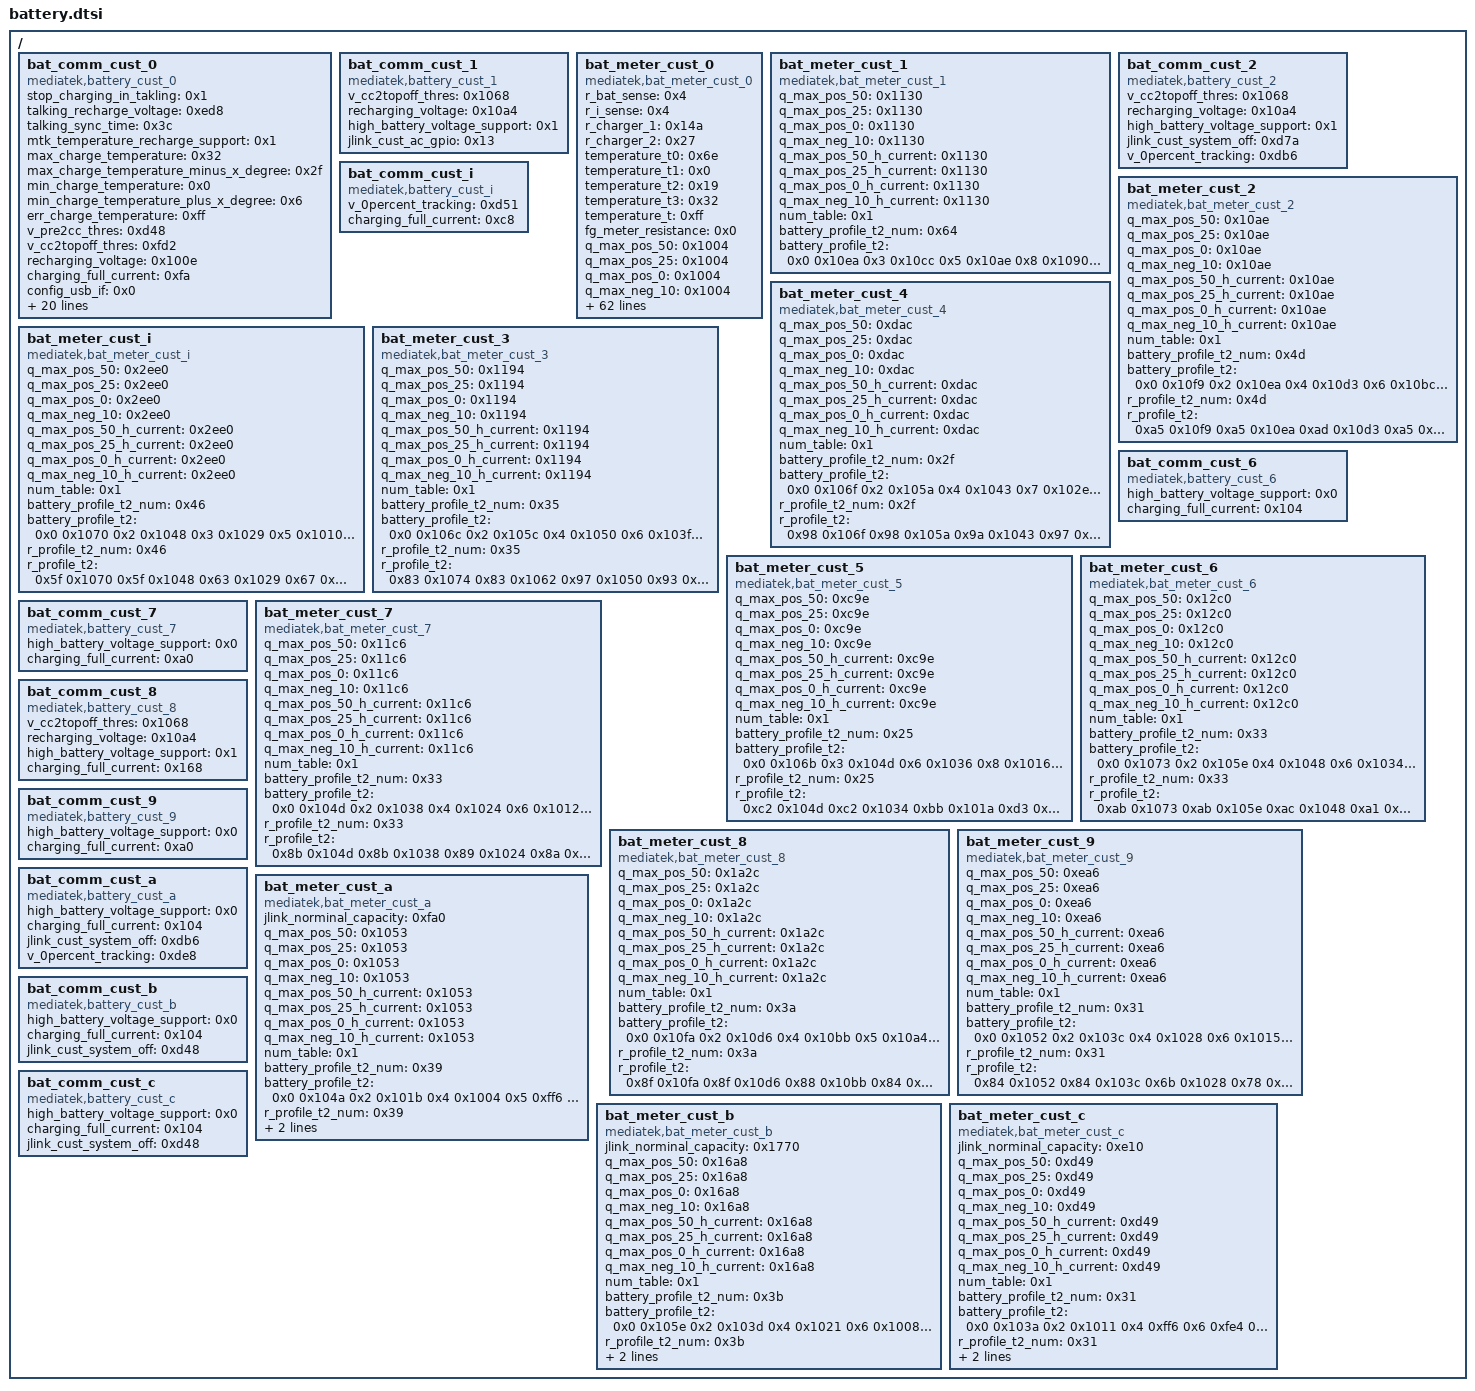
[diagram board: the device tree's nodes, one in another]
/ {
	bat_comm_cust_0 {
		compatible = "mediatek,battery_cust_0";
		stop_charging_in_takling = <0x1>;
		talking_recharge_voltage = <0xed8>;
		talking_sync_time = <0x3c>;
		mtk_temperature_recharge_support = <0x1>;
		max_charge_temperature = <0x32>;
		max_charge_temperature_minus_x_degree = <0x2f>;
		min_charge_temperature = <0x0>;
		min_charge_temperature_plus_x_degree = <0x6>;
		err_charge_temperature = <0xff>;
		v_pre2cc_thres = <0xd48>;
		v_cc2topoff_thres = <0xfd2>;
		recharging_voltage = <0x100e>;
		charging_full_current = <0xfa>;
		config_usb_if = <0x0>;
		usb_charger_current_suspend = <0x0>;
		usb_charger_current_unconfigured = <0x1b58>;
		usb_charger_current_configured = <0xc350>;
		usb_charger_current = <0xc350>;
		ac_charger_current = <0x347d8>;
		non_std_ac_charger_current = <0x347d8>;
		charging_host_charger_current = <0x347d8>;
		apple_0_5a_charger_current = <0xc350>;
		apple_1_0a_charger_current = <0x347d8>;
		apple_2_1a_charger_current = <0x347d8>;
		bat_low_temp_protect_enable = <0x0>;
		v_charger_enable = <0x0>;
		v_charger_max = <0x1964>;
		v_charger_min = <0x1130>;
		onehundred_percent_tracking_time = <0xa>;
		npercent_tracking_time = <0x14>;
		sync_to_real_tracking_time = <0x3c>;
		v_0percent_tracking = <0xd7a>;
		high_battery_voltage_support = <0x0>;
		jlink_cust_ac_gpio = <0x13>;
	};

	bat_comm_cust_1 {
		compatible = "mediatek,battery_cust_1";
		v_cc2topoff_thres = <0x1068>;
		recharging_voltage = <0x10a4>;
		high_battery_voltage_support = <0x1>;
		jlink_cust_ac_gpio = <0x13>;
	};

	bat_meter_cust_0 {
		compatible = "mediatek,bat_meter_cust_0";
		r_bat_sense = <0x4>;
		r_i_sense = <0x4>;
		r_charger_1 = <0x14a>;
		r_charger_2 = <0x27>;
		temperature_t0 = <0x6e>;
		temperature_t1 = <0x0>;
		temperature_t2 = <0x19>;
		temperature_t3 = <0x32>;
		temperature_t = <0xff>;
		fg_meter_resistance = <0x0>;
		q_max_pos_50 = <0x1004>;
		q_max_pos_25 = <0x1004>;
		q_max_pos_0 = <0x1004>;
		q_max_neg_10 = <0x1004>;
		q_max_pos_50_h_current = <0x1004>;
		q_max_pos_25_h_current = <0x1004>;
		q_max_pos_0_h_current = <0x1004>;
		q_max_neg_10_h_current = <0x1004>;
		oam_d5 = <0x1>;
		change_tracking_point = <0x1>;
		cust_tracking_point = <0x1>;
		cust_r_sense = <0x38>;
		cust_hw_cc = <0x0>;
		aging_tuning_value = <0x67>;
		cust_r_fg_offset = <0x0>;
		ocv_board_compesate = <0x0>;
		r_fg_board_base = <0x3e8>;
		r_fg_board_slope = <0x3e8>;
		car_tune_value = <0x5e>;
		car_tune_value_pb_v1 = <0x5e>;
		car_tune_value_pb_v2 = <0x5e>;
		current_detect_r_fg = <0xa>;
		minerroroffset = <0x3e8>;
		fg_vbat_average_size = <0x12>;
		r_fg_value = <0xa>;
		cust_poweron_delta_capacity_tolrance = <0x1e>;
		cust_poweron_low_capacity_tolrance = <0x5>;
		cust_poweron_max_vbat_tolrance = <0x5a>;
		cust_poweron_delta_vbat_tolrance = <0x1e>;
		cust_poweron_delta_hw_sw_ocv_capacity_tolrance = <0xa>;
		fixed_tbat_25 = <0x0>;
		vbat_normal_wakeup = <0xe10>;
		vbat_low_power_wakeup = <0xdac>;
		normal_wakeup_period = <0x1518>;
		low_power_wakeup_period = <0x12c>;
		close_poweroff_wakeup_period = <0x1e>;
		rbat_pull_up_r = <0x4204>;
		rbat_pull_up_volt = <0x708>;
		batt_temperature_table_num = <0x11>;
		batt_temperature_table = <0xffffffec 0x10a8d 0xfffffff1 0xd192 0xfffffff6 0xa60a 0xfffffffb 0x8464 0x0 0x6a53 0x5 0x5605 0xa 0x4606 0xf 0x3952 0x14 0x2f31 0x19 0x2710 0x1e 0x207b 0x23 0x1b24 0x28 0x16ca 0x2d 0x1335 0x32 0x1041 0x37 0xdcf 0x3c 0xbc6>;
		battery_profile_t0_num = <0x64>;
		battery_profile_t0 = <0x0 0x1041 0x3 0x1022 0x7 0x1010 0xa 0xffa 0xf 0xfdf 0x14 0xfb5 0x19 0xf8c 0x1e 0xf74 0x23 0xf5b 0x28 0xf43 0x2d 0xf14 0x32 0xf04 0x37 0xeee 0x3c 0xeda 0x40 0xed0 0x44 0xec8 0x46 0xec6 0x49 0xec3 0x4c 0xec2 0x4f 0xeba 0x52 0xeb5 0x53 0xeb0 0x55 0xea8 0x58 0xea5 0x5b 0xea0 0x5d 0xe82 0x5e 0xe6e 0x5f 0xe63 0x60 0xe59 0x62 0xe4a 0x63 0xdbc 0x64 0xd9d 0x64 0xd65 0x64 0xd65 0x64 0xd65 0x64 0xd65 0x64 0xd65 0x64 0xd65 0x64 0xd65 0x64 0xd65 0x64 0xd65 0x64 0xd65 0x64 0xd65 0x64 0xd65 0x64 0xd65 0x64 0xd65 0x64 0xd65 0x64 0xd65 0x64 0xd65 0x64 0xd65 0x64 0xd65 0x64 0xd65 0x64 0xd65 0x64 0xd65 0x64 0xd65 0x64 0xd65 0x64 0xd65 0x64 0xd65 0x64 0xd65 0x64 0xdaa 0x64 0xda7 0x64 0xda3 0x64 0xda0 0x64 0xd9f 0x64 0xd9b 0x64 0xd9a 0x64 0xd97 0x64 0xd97 0x64 0xd94 0x64 0xd93 0x64 0xd91 0x64 0xd90 0x64 0xd8c 0x64 0xd8b 0x64 0xd8a 0x64 0xd87 0x64 0xd87 0x64 0xd87 0x64 0xd87 0x64 0xd87 0x64 0xd87 0x64 0xd87 0x64 0xd87 0x64 0xd87 0x64 0xd87 0x64 0xd87 0x64 0xd87 0x64 0xd87 0x64 0xd87 0x64 0xd87 0x64 0xd87 0x64 0xd87 0x64 0xd87 0x64 0xc41 0x64 0xc41 0x64 0xc41 0x64 0xc41 0x64 0xc41 0x64 0xc41 0x64 0xc41>;
		battery_profile_t1_num = <0x64>;
		battery_profile_t1 = <0x0 0x1041 0x3 0x1022 0x7 0x1010 0xa 0xffa 0xf 0xfdf 0x14 0xfb5 0x19 0xf8c 0x1e 0xf74 0x23 0xf5b 0x28 0xf43 0x2d 0xf14 0x32 0xf04 0x37 0xeee 0x3c 0xeda 0x40 0xed0 0x44 0xec8 0x46 0xec6 0x49 0xec3 0x4c 0xec2 0x4f 0xeba 0x52 0xeb5 0x53 0xeb0 0x55 0xea8 0x58 0xea5 0x5b 0xea0 0x5d 0xe82 0x5e 0xe6e 0x5f 0xe63 0x60 0xe59 0x62 0xe4a 0x63 0xdbc 0x64 0xd9d 0x64 0xd65 0x64 0xd65 0x64 0xd65 0x64 0xd65 0x64 0xd65 0x64 0xd65 0x64 0xd65 0x64 0xd65 0x64 0xd65 0x64 0xd65 0x64 0xd65 0x64 0xd65 0x64 0xd65 0x64 0xd65 0x64 0xd65 0x64 0xd65 0x64 0xd65 0x64 0xd65 0x64 0xd65 0x64 0xd65 0x64 0xd65 0x64 0xd65 0x64 0xd65 0x64 0xd65 0x64 0xd65 0x64 0xd65 0x64 0xd65 0x64 0xdaa 0x64 0xda7 0x64 0xda3 0x64 0xda0 0x64 0xd9f 0x64 0xd9b 0x64 0xd9a 0x64 0xd97 0x64 0xd97 0x64 0xd94 0x64 0xd93 0x64 0xd91 0x64 0xd90 0x64 0xd8c 0x64 0xd8b 0x64 0xd8a 0x64 0xd87 0x64 0xd87 0x64 0xd87 0x64 0xd87 0x64 0xd87 0x64 0xd87 0x64 0xd87 0x64 0xd87 0x64 0xd87 0x64 0xd87 0x64 0xd87 0x64 0xd87 0x64 0xd87 0x64 0xd87 0x64 0xd87 0x64 0xd87 0x64 0xd87 0x64 0xd87 0x64 0xc41 0x64 0xc41 0x64 0xc41 0x64 0xc41 0x64 0xc41 0x64 0xc41 0x64 0xc41>;
		battery_profile_t2_num = <0x64>;
		battery_profile_t2 = <0x0 0x1041 0x3 0x1022 0x7 0x1010 0xa 0xffa 0xf 0xfdf 0x14 0xfb5 0x19 0xf8c 0x1e 0xf74 0x23 0xf5b 0x28 0xf43 0x2d 0xf14 0x32 0xf04 0x37 0xeee 0x3c 0xeda 0x40 0xed0 0x44 0xec8 0x46 0xec6 0x49 0xec3 0x4c 0xec2 0x4f 0xeba 0x52 0xeb5 0x53 0xeb0 0x55 0xea8 0x58 0xea5 0x5b 0xea0 0x5d 0xe82 0x5e 0xe6e 0x5f 0xe63 0x60 0xe59 0x62 0xe4a 0x63 0xdbc 0x64 0xd9d 0x64 0xd65 0x64 0xd65 0x64 0xd65 0x64 0xd65 0x64 0xd65 0x64 0xd65 0x64 0xd65 0x64 0xd65 0x64 0xd65 0x64 0xd65 0x64 0xd65 0x64 0xd65 0x64 0xd65 0x64 0xd65 0x64 0xd65 0x64 0xd65 0x64 0xd65 0x64 0xd65 0x64 0xd65 0x64 0xd65 0x64 0xd65 0x64 0xd65 0x64 0xd65 0x64 0xd65 0x64 0xd65 0x64 0xd65 0x64 0xd65 0x64 0xdaa 0x64 0xda7 0x64 0xda3 0x64 0xda0 0x64 0xd9f 0x64 0xd9b 0x64 0xd9a 0x64 0xd97 0x64 0xd97 0x64 0xd94 0x64 0xd93 0x64 0xd91 0x64 0xd90 0x64 0xd8c 0x64 0xd8b 0x64 0xd8a 0x64 0xd87 0x64 0xd87 0x64 0xd87 0x64 0xd87 0x64 0xd87 0x64 0xd87 0x64 0xd87 0x64 0xd87 0x64 0xd87 0x64 0xd87 0x64 0xd87 0x64 0xd87 0x64 0xd87 0x64 0xd87 0x64 0xd87 0x64 0xd87 0x64 0xd87 0x64 0xd87 0x64 0xc41 0x64 0xc41 0x64 0xc41 0x64 0xc41 0x64 0xc41 0x64 0xc41 0x64 0xc41>;
		battery_profile_t3_num = <0x64>;
		battery_profile_t3 = <0x0 0x1041 0x3 0x1022 0x7 0x1010 0xa 0xffa 0xf 0xfdf 0x14 0xfb5 0x19 0xf8c 0x1e 0xf74 0x23 0xf5b 0x28 0xf43 0x2d 0xf14 0x32 0xf04 0x37 0xeee 0x3c 0xeda 0x40 0xed0 0x44 0xec8 0x46 0xec6 0x49 0xec3 0x4c 0xec2 0x4f 0xeba 0x52 0xeb5 0x53 0xeb0 0x55 0xea8 0x58 0xea5 0x5b 0xea0 0x5d 0xe82 0x5e 0xe6e 0x5f 0xe63 0x60 0xe59 0x62 0xe4a 0x63 0xdbc 0x64 0xd9d 0x64 0xd65 0x64 0xd65 0x64 0xd65 0x64 0xd65 0x64 0xd65 0x64 0xd65 0x64 0xd65 0x64 0xd65 0x64 0xd65 0x64 0xd65 0x64 0xd65 0x64 0xd65 0x64 0xd65 0x64 0xd65 0x64 0xd65 0x64 0xd65 0x64 0xd65 0x64 0xd65 0x64 0xd65 0x64 0xd65 0x64 0xd65 0x64 0xd65 0x64 0xd65 0x64 0xd65 0x64 0xd65 0x64 0xd65 0x64 0xd65 0x64 0xdaa 0x64 0xda7 0x64 0xda3 0x64 0xda0 0x64 0xd9f 0x64 0xd9b 0x64 0xd9a 0x64 0xd97 0x64 0xd97 0x64 0xd94 0x64 0xd93 0x64 0xd91 0x64 0xd90 0x64 0xd8c 0x64 0xd8b 0x64 0xd8a 0x64 0xd87 0x64 0xd87 0x64 0xd87 0x64 0xd87 0x64 0xd87 0x64 0xd87 0x64 0xd87 0x64 0xd87 0x64 0xd87 0x64 0xd87 0x64 0xd87 0x64 0xd87 0x64 0xd87 0x64 0xd87 0x64 0xd87 0x64 0xd87 0x64 0xd87 0x64 0xd87 0x64 0xc41 0x64 0xc41 0x64 0xc41 0x64 0xc41 0x64 0xc41 0x64 0xc41 0x64 0xc41>;
		r_profile_t0_num = <0x64>;
		r_profile_t0 = <0x70 0x1041 0x70 0x103e 0x75 0x1023 0x75 0x100c 0x75 0xff5 0x73 0xfdf 0x6f 0xfcc 0x71 0xfb8 0x75 0xfa6 0x70 0xf92 0x6e 0xf84 0x75 0xf73 0x76 0xf62 0x70 0xf54 0x75 0xf42 0x71 0xf35 0x70 0xf25 0x71 0xf14 0x6e 0xf06 0x70 0xef6 0x71 0xeed 0x70 0xee2 0x70 0xed9 0x6e 0xed0 0x75 0xec5 0x75 0xec4 0x70 0xebd 0x6e 0xeb9 0x71 0xeb3 0x76 0xeb0 0x73 0xeaa 0x76 0xea6 0x75 0xea1 0x70 0xe9d 0x70 0xe95 0x70 0xe8f 0x71 0xe87 0x71 0xe7c 0x75 0xe6f 0x76 0xe60 0x75 0xe55 0x71 0xe47 0x6e 0xe2f 0x71 0xdeb 0x73 0xdbe 0xc3 0xd50 0xc3 0xd50 0xc3 0xd50 0xc3 0xd50 0xc3 0xd50 0xc3 0xd50 0xc3 0xd15 0xc3 0xd01 0xc3 0xcf7 0xc3 0xcf1 0xc3 0xced 0xc3 0xce8 0xc3 0xce6 0xc3 0xce4 0xc3 0xce0 0xc3 0xcdf 0xc3 0xce1 0xc3 0xce0 0xc3 0xce0 0xc3 0xce0 0xc3 0xcdd 0xc3 0xcd9 0xc3 0xcd9 0xc3 0xcd6 0xc3 0xcd5 0xc3 0xcd4 0xc3 0xcd4 0xc3 0xcd4 0xc3 0xcd4 0xc3 0xcd3 0xc3 0xcd2 0xc3 0xcd1 0xc3 0xcd1 0xc3 0xcd1 0xc3 0xcd1 0xc3 0xcd1 0xc3 0xcd1 0xc3 0xcd1 0xc3 0xcd1 0xc3 0xcd1 0xc3 0xcd1 0xc3 0xcd1 0xc3 0xcd1 0xc3 0xcd1 0xc3 0xcd1 0xc3 0xcd1 0xc3 0xcd1 0xc3 0xcd1 0x2bf 0xb86 0x24e 0xb85 0x1d9 0xb83 0x2b5 0xb80 0x2d5 0xb7b 0x1e3 0xb78 0x1e0 0xb73>;
		r_profile_t1_num = <0x64>;
		r_profile_t1 = <0x70 0x1041 0x70 0x103e 0x75 0x1023 0x75 0x100c 0x75 0xff5 0x73 0xfdf 0x6f 0xfcc 0x71 0xfb8 0x75 0xfa6 0x70 0xf92 0x6e 0xf84 0x75 0xf73 0x76 0xf62 0x70 0xf54 0x75 0xf42 0x71 0xf35 0x70 0xf25 0x71 0xf14 0x6e 0xf06 0x70 0xef6 0x71 0xeed 0x70 0xee2 0x70 0xed9 0x6e 0xed0 0x75 0xec5 0x75 0xec4 0x70 0xebd 0x6e 0xeb9 0x71 0xeb3 0x76 0xeb0 0x73 0xeaa 0x76 0xea6 0x75 0xea1 0x70 0xe9d 0x70 0xe95 0x70 0xe8f 0x71 0xe87 0x71 0xe7c 0x75 0xe6f 0x76 0xe60 0x75 0xe55 0x71 0xe47 0x6e 0xe2f 0x71 0xdeb 0x73 0xdbe 0xc3 0xd50 0xc3 0xd50 0xc3 0xd50 0xc3 0xd50 0xc3 0xd50 0xc3 0xd50 0xc3 0xd15 0xc3 0xd01 0xc3 0xcf7 0xc3 0xcf1 0xc3 0xced 0xc3 0xce8 0xc3 0xce6 0xc3 0xce4 0xc3 0xce0 0xc3 0xcdf 0xc3 0xce1 0xc3 0xce0 0xc3 0xce0 0xc3 0xce0 0xc3 0xcdd 0xc3 0xcd9 0xc3 0xcd9 0xc3 0xcd6 0xc3 0xcd5 0xc3 0xcd4 0xc3 0xcd4 0xc3 0xcd4 0xc3 0xcd4 0xc3 0xcd3 0xc3 0xcd2 0xc3 0xcd1 0xc3 0xcd1 0xc3 0xcd1 0xc3 0xcd1 0xc3 0xcd1 0xc3 0xcd1 0xc3 0xcd1 0xc3 0xcd1 0xc3 0xcd1 0xc3 0xcd1 0xc3 0xcd1 0xc3 0xcd1 0xc3 0xcd1 0xc3 0xcd1 0xc3 0xcd1 0xc3 0xcd1 0xc3 0xcd1 0x2bf 0xb86 0x24e 0xb85 0x1d9 0xb83 0x2b5 0xb80 0x2d5 0xb7b 0x1e3 0xb78 0x1e0 0xb73>;
		r_profile_t2_num = <0x64>;
		r_profile_t2 = <0x70 0x1041 0x70 0x103e 0x75 0x1023 0x75 0x100c 0x75 0xff5 0x73 0xfdf 0x6f 0xfcc 0x71 0xfb8 0x75 0xfa6 0x70 0xf92 0x6e 0xf84 0x75 0xf73 0x76 0xf62 0x70 0xf54 0x75 0xf42 0x71 0xf35 0x70 0xf25 0x71 0xf14 0x6e 0xf06 0x70 0xef6 0x71 0xeed 0x70 0xee2 0x70 0xed9 0x6e 0xed0 0x75 0xec5 0x75 0xec4 0x70 0xebd 0x6e 0xeb9 0x71 0xeb3 0x76 0xeb0 0x73 0xeaa 0x76 0xea6 0x75 0xea1 0x70 0xe9d 0x70 0xe95 0x70 0xe8f 0x71 0xe87 0x71 0xe7c 0x75 0xe6f 0x76 0xe60 0x75 0xe55 0x71 0xe47 0x6e 0xe2f 0x71 0xdeb 0x73 0xdbe 0xc3 0xd50 0xc3 0xd50 0xc3 0xd50 0xc3 0xd50 0xc3 0xd50 0xc3 0xd50 0xc3 0xd15 0xc3 0xd01 0xc3 0xcf7 0xc3 0xcf1 0xc3 0xced 0xc3 0xce8 0xc3 0xce6 0xc3 0xce4 0xc3 0xce0 0xc3 0xcdf 0xc3 0xce1 0xc3 0xce0 0xc3 0xce0 0xc3 0xce0 0xc3 0xcdd 0xc3 0xcd9 0xc3 0xcd9 0xc3 0xcd6 0xc3 0xcd5 0xc3 0xcd4 0xc3 0xcd4 0xc3 0xcd4 0xc3 0xcd4 0xc3 0xcd3 0xc3 0xcd2 0xc3 0xcd1 0xc3 0xcd1 0xc3 0xcd1 0xc3 0xcd1 0xc3 0xcd1 0xc3 0xcd1 0xc3 0xcd1 0xc3 0xcd1 0xc3 0xcd1 0xc3 0xcd1 0xc3 0xcd1 0xc3 0xcd1 0xc3 0xcd1 0xc3 0xcd1 0xc3 0xcd1 0xc3 0xcd1 0xc3 0xcd1 0x2bf 0xb86 0x24e 0xb85 0x1d9 0xb83 0x2b5 0xb80 0x2d5 0xb7b 0x1e3 0xb78 0x1e0 0xb73>;
		r_profile_t3_num = <0x64>;
		r_profile_t3 = <0x70 0x1041 0x70 0x103e 0x75 0x1023 0x75 0x100c 0x75 0xff5 0x73 0xfdf 0x6f 0xfcc 0x71 0xfb8 0x75 0xfa6 0x70 0xf92 0x6e 0xf84 0x75 0xf73 0x76 0xf62 0x70 0xf54 0x75 0xf42 0x71 0xf35 0x70 0xf25 0x71 0xf14 0x6e 0xf06 0x70 0xef6 0x71 0xeed 0x70 0xee2 0x70 0xed9 0x6e 0xed0 0x75 0xec5 0x75 0xec4 0x70 0xebd 0x6e 0xeb9 0x71 0xeb3 0x76 0xeb0 0x73 0xeaa 0x76 0xea6 0x75 0xea1 0x70 0xe9d 0x70 0xe95 0x70 0xe8f 0x71 0xe87 0x71 0xe7c 0x75 0xe6f 0x76 0xe60 0x75 0xe55 0x71 0xe47 0x6e 0xe2f 0x71 0xdeb 0x73 0xdbe 0xc3 0xd50 0xc3 0xd50 0xc3 0xd50 0xc3 0xd50 0xc3 0xd50 0xc3 0xd50 0xc3 0xd15 0xc3 0xd01 0xc3 0xcf7 0xc3 0xcf1 0xc3 0xced 0xc3 0xce8 0xc3 0xce6 0xc3 0xce4 0xc3 0xce0 0xc3 0xcdf 0xc3 0xce1 0xc3 0xce0 0xc3 0xce0 0xc3 0xce0 0xc3 0xcdd 0xc3 0xcd9 0xc3 0xcd9 0xc3 0xcd6 0xc3 0xcd5 0xc3 0xcd4 0xc3 0xcd4 0xc3 0xcd4 0xc3 0xcd4 0xc3 0xcd3 0xc3 0xcd2 0xc3 0xcd1 0xc3 0xcd1 0xc3 0xcd1 0xc3 0xcd1 0xc3 0xcd1 0xc3 0xcd1 0xc3 0xcd1 0xc3 0xcd1 0xc3 0xcd1 0xc3 0xcd1 0xc3 0xcd1 0xc3 0xcd1 0xc3 0xcd1 0xc3 0xcd1 0xc3 0xcd1 0xc3 0xcd1 0xc3 0xcd1 0x2bf 0xb86 0x24e 0xb85 0x1d9 0xb83 0x2b5 0xb80 0x2d5 0xb7b 0x1e3 0xb78 0x1e0 0xb73>;
	};

	bat_meter_cust_1 {
		compatible = "mediatek,bat_meter_cust_1";
		q_max_pos_50 = <0x1130>;
		q_max_pos_25 = <0x1130>;
		q_max_pos_0 = <0x1130>;
		q_max_neg_10 = <0x1130>;
		q_max_pos_50_h_current = <0x1130>;
		q_max_pos_25_h_current = <0x1130>;
		q_max_pos_0_h_current = <0x1130>;
		q_max_neg_10_h_current = <0x1130>;
		num_table = <0x1>;
		battery_profile_t2_num = <0x64>;
		battery_profile_t2 = <0x0 0x10ea 0x3 0x10cc 0x5 0x10ae 0x8 0x1090 0xb 0x1068 0xd 0x1040 0x10 0x1022 0x12 0x1003 0x15 0xfee 0x18 0xfcf 0x1a 0xfbb 0x1e 0xf8f 0x21 0xf8c 0x24 0xf75 0x27 0xf52 0x2a 0xf4a 0x2d 0xf3f 0x2f 0xf24 0x33 0xf1b 0x36 0xf08 0x39 0xef1 0x3c 0xee5 0x3e 0xee3 0x41 0xed6 0x44 0xeca 0x46 0xebf 0x49 0xeb8 0x4c 0xeb3 0x4f 0xea9 0x51 0xea7 0x52 0xea4 0x54 0xe9d 0x56 0xe93 0x57 0xe85 0x59 0xe7a 0x5a 0xe72 0x5c 0xe69 0x5d 0xe60 0x60 0xe56 0x61 0xe46 0x62 0xe36 0x63 0xdb9 0x64 0xd59 0x64 0xd59 0x64 0xd59 0x64 0xd59 0x64 0xd59 0x64 0xd59 0x64 0xd59 0x64 0xd59 0x64 0xd59 0x64 0xd59 0x64 0xd59 0x64 0xd59 0x64 0xd59 0x64 0xd59 0x64 0xd59 0x64 0xd59 0x64 0xd59 0x64 0xd59 0x64 0xd59 0x64 0xd59 0x64 0xd59 0x64 0xd59 0x64 0xd59 0x64 0xd59 0x64 0xd59 0x64 0xd59 0x64 0xd59 0x64 0xd59 0x64 0xd58 0x64 0xd55 0x64 0xd54 0x64 0xc85 0x64 0xc06 0x64 0xbd7 0x64 0xbc5 0x64 0xbc5 0x64 0xbc5 0x64 0xbc5 0x64 0xbc5 0x64 0xbc5 0x64 0xbc5 0x64 0xbc5 0x64 0xbc5 0x64 0xbc5 0x64 0xbc5 0x64 0xbc5 0x64 0xbc5 0x64 0xbc5 0x64 0xbc5 0x64 0xbc5 0x64 0xbc5 0x64 0xbc5 0x64 0xbc5 0x64 0xbc5 0x64 0xbc5 0x64 0xbc5 0x64 0xbc5 0x64 0xbc5>;
	};

	bat_comm_cust_2 {
		compatible = "mediatek,battery_cust_2";
		v_cc2topoff_thres = <0x1068>;
		recharging_voltage = <0x10a4>;
		high_battery_voltage_support = <0x1>;
		jlink_cust_system_off = <0xd7a>;
		v_0percent_tracking = <0xdb6>;
	};

	bat_meter_cust_2 {
		compatible = "mediatek,bat_meter_cust_2";
		q_max_pos_50 = <0x10ae>;
		q_max_pos_25 = <0x10ae>;
		q_max_pos_0 = <0x10ae>;
		q_max_neg_10 = <0x10ae>;
		q_max_pos_50_h_current = <0x10ae>;
		q_max_pos_25_h_current = <0x10ae>;
		q_max_pos_0_h_current = <0x10ae>;
		q_max_neg_10_h_current = <0x10ae>;
		num_table = <0x1>;
		battery_profile_t2_num = <0x4d>;
		battery_profile_t2 = <0x0 0x10f9 0x2 0x10ea 0x4 0x10d3 0x6 0x10bc 0x8 0x10a7 0xa 0x1091 0xc 0x107c 0xe 0x1067 0x10 0x1052 0x12 0x103e 0x14 0x102a 0x16 0x1016 0x17 0x1003 0x19 0xff3 0x1b 0xfe7 0x1d 0xfca 0x1f 0xfab 0x21 0xf9b 0x23 0xf92 0x25 0xf88 0x27 0xf78 0x29 0xf67 0x2b 0xf53 0x2d 0xf40 0x2f 0xf2f 0x31 0xf21 0x33 0xf15 0x35 0xf0b 0x37 0xf02 0x39 0xefa 0x3b 0xef3 0x3d 0xeec 0x3f 0xee5 0x41 0xedf 0x43 0xed9 0x45 0xed5 0x47 0xece 0x48 0xec9 0x4a 0xec1 0x4c 0xebb 0x4e 0xeb3 0x50 0xeab 0x52 0xea5 0x54 0xe9d 0x56 0xe91 0x58 0xe88 0x5a 0xe78 0x5c 0xe73 0x5e 0xe71 0x60 0xe6c 0x62 0xe48 0x63 0xe04 0x64 0xd97 0x64 0xd65 0x64 0xcf6 0x64 0xc92 0x64 0xc92 0x64 0xc92 0x64 0xc92 0x64 0xc92 0x64 0xc92 0x64 0xc92 0x64 0xc92 0x64 0xc92 0x64 0xc92 0x64 0xc92 0x64 0xc92 0x64 0xc92 0x64 0xc92 0x64 0xc92 0x64 0xc92 0x64 0xc92 0x64 0xc92 0x64 0xc92 0x64 0xc92 0x64 0xc92 0x64 0xc92>;
		r_profile_t2_num = <0x4d>;
		r_profile_t2 = <0xa5 0x10f9 0xa5 0x10ea 0xad 0x10d3 0xa5 0x10bc 0xac 0x10a7 0xa2 0x1091 0xaa 0x107c 0xa2 0x1067 0xaa 0x1052 0xae 0x103e 0xad 0x102a 0xae 0x1016 0xae 0x1003 0xb9 0xff3 0xb9 0xfe7 0xb3 0xfca 0xb0 0xfab 0xb1 0xf9b 0xba 0xf92 0xba 0xf88 0xbb 0xf78 0xb9 0xf67 0xa9 0xf53 0xa8 0xf40 0x9d 0xf2f 0xa1 0xf21 0x98 0xf15 0x99 0xf0b 0x9a 0xf02 0x9b 0xefa 0x9d 0xef3 0x8f 0xeec 0x91 0xee5 0xa6 0xedf 0x96 0xed9 0xa1 0xed5 0x9b 0xece 0x9e 0xec9 0x9f 0xec1 0x9e 0xebb 0x96 0xeb3 0x98 0xeab 0xa0 0xea5 0xa4 0xe9d 0x9f 0xe91 0x9d 0xe88 0xa1 0xe78 0xa5 0xe73 0xa9 0xe71 0xb0 0xe6c 0xad 0xe48 0xb4 0xde6 0xd1 0xd29 0xb9 0xd01 0xaa 0xc92 0xaa 0xc92 0xaa 0xc92 0xaa 0xc92 0xaa 0xc92 0xaa 0xc92 0xaa 0xc92 0xaa 0xc92 0xaa 0xc92 0xaa 0xc92 0xaa 0xc92 0xaa 0xc92 0xaa 0xc92 0xaa 0xc92 0xaa 0xc92 0xaa 0xc92 0xaa 0xc92 0xaa 0xc92 0xaa 0xc92 0xaa 0xc92 0xaa 0xc92 0xaa 0xc92 0xaa 0xc92>;
	};

	bat_comm_cust_i {
		compatible = "mediatek,battery_cust_i";
		v_0percent_tracking = <0xd51>;
		charging_full_current = <0xc8>;
	};

	bat_meter_cust_i {
		compatible = "mediatek,bat_meter_cust_i";
		q_max_pos_50 = <0x2ee0>;
		q_max_pos_25 = <0x2ee0>;
		q_max_pos_0 = <0x2ee0>;
		q_max_neg_10 = <0x2ee0>;
		q_max_pos_50_h_current = <0x2ee0>;
		q_max_pos_25_h_current = <0x2ee0>;
		q_max_pos_0_h_current = <0x2ee0>;
		q_max_neg_10_h_current = <0x2ee0>;
		num_table = <0x1>;
		battery_profile_t2_num = <0x46>;
		battery_profile_t2 = <0x0 0x1070 0x2 0x1048 0x3 0x1029 0x5 0x1010 0x7 0xff9 0x8 0xfe5 0xa 0xfd1 0xb 0xfbe 0xd 0xfac 0xf 0xf9a 0x10 0xf88 0x12 0xf77 0x14 0xf67 0x15 0xf57 0x17 0xf46 0x18 0xf37 0x1a 0xf27 0x1c 0xf18 0x1d 0xf09 0x1f 0xefb 0x21 0xeed 0x22 0xedf 0x24 0xed2 0x25 0xec5 0x27 0xeb9 0x29 0xeae 0x2a 0xea3 0x2c 0xe99 0x2e 0xe8e 0x2f 0xe82 0x31 0xe74 0x32 0xe66 0x34 0xe5a 0x36 0xe50 0x37 0xe48 0x39 0xe42 0x3b 0xe3c 0x3c 0xe37 0x3e 0xe32 0x40 0xe2f 0x41 0xe2a 0x43 0xe26 0x44 0xe22 0x46 0xe1f 0x48 0xe1c 0x49 0xe17 0x4b 0xe13 0x4d 0xe10 0x4e 0xe0b 0x50 0xe06 0x51 0xdff 0x53 0xdf7 0x55 0xdee 0x56 0xde4 0x58 0xddb 0x5a 0xdcf 0x5b 0xdc9 0x5d 0xdbf 0x5e 0xdb3 0x60 0xda7 0x62 0xd99 0x63 0xd8c 0x64 0xd7d 0x64 0xd73 0x64 0xd69 0x64 0xd5b 0x64 0xd42 0x64 0xd03 0x64 0xce7 0x64 0xce1>;
		r_profile_t2_num = <0x46>;
		r_profile_t2 = <0x5f 0x1070 0x5f 0x1048 0x63 0x1029 0x67 0x1010 0x52 0xff9 0x5b 0xfe5 0x5f 0xfd1 0x5d 0xfbe 0x56 0xfac 0x54 0xf9a 0x5f 0xf88 0x54 0xf77 0x60 0xf67 0x62 0xf57 0x5b 0xf46 0x54 0xf37 0x5f 0xf27 0x52 0xf18 0x54 0xf09 0x53 0xefb 0x5e 0xeed 0x5f 0xedf 0x68 0xed2 0x56 0xec5 0x5d 0xeb9 0x68 0xeae 0x64 0xea3 0x6b 0xe99 0x5e 0xe8e 0x63 0xe82 0x65 0xe74 0x65 0xe66 0x64 0xe5a 0x5c 0xe50 0x5b 0xe48 0x53 0xe42 0x5b 0xe3c 0x5b 0xe37 0x59 0xe32 0x58 0xe2f 0x53 0xe2a 0x58 0xe26 0x5b 0xe22 0x59 0xe1f 0x56 0xe1c 0x5b 0xe17 0x5e 0xe13 0x59 0xe10 0x58 0xe0b 0x5f 0xe06 0x59 0xdff 0x5e 0xdf7 0x55 0xdee 0x58 0xde4 0x64 0xddb 0x52 0xdcf 0x65 0xdc9 0x62 0xdbf 0x67 0xdb3 0x5f 0xda7 0x56 0xd99 0x5c 0xd8c 0x66 0xd7d 0x6a 0xd73 0x64 0xd69 0x7f 0xd5b 0x94 0xd42 0xb5 0xd03 0xb6 0xce7 0xb6 0xce1>;
	};

	bat_meter_cust_3 {
		compatible = "mediatek,bat_meter_cust_3";
		q_max_pos_50 = <0x1194>;
		q_max_pos_25 = <0x1194>;
		q_max_pos_0 = <0x1194>;
		q_max_neg_10 = <0x1194>;
		q_max_pos_50_h_current = <0x1194>;
		q_max_pos_25_h_current = <0x1194>;
		q_max_pos_0_h_current = <0x1194>;
		q_max_neg_10_h_current = <0x1194>;
		num_table = <0x1>;
		battery_profile_t2_num = <0x35>;
		battery_profile_t2 = <0x0 0x106c 0x2 0x105c 0x4 0x1050 0x6 0x103f 0x8 0x102d 0xa 0x101b 0xc 0x100a 0xe 0xff9 0x10 0xfea 0x12 0xfd9 0x13 0xfc7 0x15 0xfb8 0x17 0xfa9 0x19 0xf9a 0x1b 0xf8a 0x1d 0xf7e 0x1f 0xf70 0x21 0xf60 0x23 0xf4d 0x25 0xf3b 0x27 0xf2b 0x29 0xf1f 0x2b 0xf14 0x2d 0xf0b 0x2f 0xf03 0x31 0xefb 0x33 0xef3 0x35 0xeed 0x37 0xee7 0x39 0xee0 0x3a 0xeda 0x3c 0xed5 0x3e 0xecf 0x40 0xeca 0x42 0xec6 0x44 0xec1 0x46 0xebc 0x48 0xeb7 0x4a 0xeb1 0x4c 0xea9 0x4e 0xea0 0x50 0xe99 0x52 0xe8c 0x54 0xe7d 0x56 0xe6d 0x58 0xe68 0x5a 0xe66 0x5c 0xe64 0x5e 0xe61 0x5f 0xe57 0x61 0xe1f 0x63 0xdbf 0x64 0xd89>;
		r_profile_t2_num = <0x35>;
		r_profile_t2 = <0x83 0x1074 0x83 0x1062 0x97 0x1050 0x93 0x103f 0x96 0x102d 0x86 0x101b 0x88 0x100a 0x9a 0xff9 0x87 0xfea 0x95 0xfd9 0x8b 0xfc7 0x9a 0xfb8 0x90 0xfa9 0xa5 0xf9a 0x99 0xf8a 0xae 0xf7e 0x9d 0xf70 0x94 0xf60 0x9b 0xf4d 0x99 0xf3b 0x81 0xf2b 0x86 0xf1f 0x90 0xf14 0x7a 0xf0b 0x82 0xf03 0x80 0xefb 0x80 0xef3 0x86 0xeed 0x8d 0xee7 0x98 0xee0 0x96 0xeda 0x93 0xed5 0x87 0xecf 0x9c 0xeca 0x98 0xec6 0x97 0xec1 0x83 0xebc 0x7b 0xeb7 0x96 0xeb1 0x8c 0xea9 0x8d 0xea0 0x90 0xe99 0x93 0xe8c 0x93 0xe7d 0x87 0xe6d 0x89 0xe68 0x89 0xe66 0x9a 0xe64 0xa1 0xe61 0xa9 0xe57 0x9f 0xe1f 0xa8 0xdbf 0xa7 0xd25>;
	};

	bat_meter_cust_4 {
		compatible = "mediatek,bat_meter_cust_4";
		q_max_pos_50 = <0xdac>;
		q_max_pos_25 = <0xdac>;
		q_max_pos_0 = <0xdac>;
		q_max_neg_10 = <0xdac>;
		q_max_pos_50_h_current = <0xdac>;
		q_max_pos_25_h_current = <0xdac>;
		q_max_pos_0_h_current = <0xdac>;
		q_max_neg_10_h_current = <0xdac>;
		num_table = <0x1>;
		battery_profile_t2_num = <0x2f>;
		battery_profile_t2 = <0x0 0x106f 0x2 0x105a 0x4 0x1043 0x7 0x102e 0x9 0x101b 0xb 0x1009 0xd 0xff8 0xf 0xfea 0x12 0xfdd 0x14 0xfd0 0x16 0xfc5 0x18 0xfba 0x1a 0xfae 0x1d 0xfa0 0x1f 0xf91 0x21 0xf81 0x23 0xf6e 0x25 0xf5b 0x28 0xf4a 0x2a 0xf3c 0x2c 0xf30 0x2e 0xf26 0x30 0xf1d 0x33 0xf13 0x35 0xf0b 0x37 0xf03 0x39 0xefb 0x3b 0xef2 0x3e 0xeea 0x40 0xee3 0x42 0xedb 0x44 0xed2 0x46 0xec6 0x49 0xeba 0x4b 0xeae 0x4d 0xea4 0x4f 0xe9c 0x51 0xe94 0x54 0xe89 0x56 0xe7f 0x58 0xe73 0x5a 0xe67 0x5c 0xe63 0x5f 0xe5b 0x61 0xe33 0x63 0xdd9 0x64 0xd98>;
		r_profile_t2_num = <0x2f>;
		r_profile_t2 = <0x98 0x106f 0x98 0x105a 0x9a 0x1043 0x97 0x102e 0x9e 0x101b 0x90 0x1009 0x9b 0xff8 0xab 0xfea 0x9f 0xfdd 0xa4 0xfd0 0xaa 0xfc5 0xab 0xfba 0xa9 0xfae 0xb8 0xfa0 0xa2 0xf91 0xb4 0xf81 0xa3 0xf6e 0x9b 0xf5b 0xa3 0xf4a 0x96 0xf3c 0x9d 0xf30 0xa0 0xf26 0x97 0xf1d 0x9a 0xf13 0x96 0xf0b 0x9d 0xf03 0x96 0xefb 0x96 0xef2 0x9b 0xeea 0xa5 0xee3 0x99 0xedb 0xa5 0xed2 0x92 0xec6 0xa2 0xeba 0x9d 0xeae 0x9d 0xea4 0x9e 0xe9c 0x99 0xe94 0xa0 0xe89 0x95 0xe7f 0x86 0xe73 0x93 0xe67 0x96 0xe63 0x9d 0xe5b 0xa9 0xe33 0xa9 0xdd9 0xae 0xd40>;
	};

	bat_meter_cust_5 {
		compatible = "mediatek,bat_meter_cust_5";
		q_max_pos_50 = <0xc9e>;
		q_max_pos_25 = <0xc9e>;
		q_max_pos_0 = <0xc9e>;
		q_max_neg_10 = <0xc9e>;
		q_max_pos_50_h_current = <0xc9e>;
		q_max_pos_25_h_current = <0xc9e>;
		q_max_pos_0_h_current = <0xc9e>;
		q_max_neg_10_h_current = <0xc9e>;
		num_table = <0x1>;
		battery_profile_t2_num = <0x25>;
		battery_profile_t2 = <0x0 0x106b 0x3 0x104d 0x6 0x1036 0x8 0x1016 0xb 0xfff 0xe 0xfdd 0x11 0xfba 0x14 0xfa6 0x17 0xf94 0x19 0xf83 0x1c 0xf71 0x1f 0xf60 0x22 0xf42 0x25 0xf24 0x27 0xf15 0x2a 0xf08 0x2d 0xefc 0x30 0xef2 0x33 0xee9 0x35 0xee0 0x38 0xed9 0x3b 0xed2 0x3e 0xecd 0x41 0xec6 0x44 0xec0 0x46 0xeb8 0x49 0xeb1 0x4c 0xea8 0x4f 0xe9f 0x52 0xe93 0x54 0xe83 0x57 0xe72 0x5a 0xe66 0x5d 0xe44 0x60 0xe28 0x62 0xdec 0x64 0xd9c>;
		r_profile_t2_num = <0x25>;
		r_profile_t2 = <0xc2 0x104d 0xc2 0x1034 0xbb 0x101a 0xd3 0x1002 0xac 0xfeb 0xbf 0xfd3 0xb0 0xfba 0xe3 0xfa6 0xdf 0xf94 0xd5 0xf83 0x102 0xf71 0xe6 0xf60 0xf2 0xf42 0xc4 0xf24 0xa9 0xf15 0xca 0xf08 0xbe 0xefc 0xc1 0xef2 0xcf 0xee9 0xcd 0xee0 0xba 0xed9 0xc8 0xed2 0xdc 0xecd 0xd5 0xec6 0xca 0xec0 0xbe 0xeb8 0xc5 0xeb1 0xb7 0xea8 0xd9 0xe9f 0xd6 0xe93 0xca 0xe83 0xcf 0xe72 0xdc 0xe66 0xd9 0xe62 0x107 0xe55 0x120 0xe00 0x17e 0xd3d>;
	};

	bat_comm_cust_6 {
		compatible = "mediatek,battery_cust_6";
		high_battery_voltage_support = <0x0>;
		charging_full_current = <0x104>;
	};

	bat_meter_cust_6 {
		compatible = "mediatek,bat_meter_cust_6";
		q_max_pos_50 = <0x12c0>;
		q_max_pos_25 = <0x12c0>;
		q_max_pos_0 = <0x12c0>;
		q_max_neg_10 = <0x12c0>;
		q_max_pos_50_h_current = <0x12c0>;
		q_max_pos_25_h_current = <0x12c0>;
		q_max_pos_0_h_current = <0x12c0>;
		q_max_neg_10_h_current = <0x12c0>;
		num_table = <0x1>;
		battery_profile_t2_num = <0x33>;
		battery_profile_t2 = <0x0 0x1073 0x2 0x105e 0x4 0x1048 0x6 0x1034 0x8 0x1021 0xa 0x100d 0xc 0xffc 0xe 0xfeb 0x10 0xfdd 0x12 0xfc7 0x14 0xfb3 0x16 0xfa1 0x18 0xf94 0x1a 0xf8b 0x1c 0xf7e 0x1e 0xf71 0x20 0xf63 0x22 0xf57 0x25 0xf4a 0x27 0xf3a 0x29 0xf2b 0x2b 0xf1c 0x2d 0xf0f 0x2f 0xf04 0x31 0xefb 0x33 0xef2 0x35 0xeeb 0x37 0xee4 0x39 0xedf 0x3b 0xed9 0x3d 0xed4 0x3f 0xed0 0x41 0xecb 0x43 0xec7 0x45 0xec2 0x47 0xebd 0x49 0xeb7 0x4b 0xeb0 0x4d 0xea9 0x4f 0xea2 0x51 0xe9c 0x53 0xe94 0x55 0xe8a 0x57 0xe7f 0x59 0xe71 0x5b 0xe69 0x5d 0xe66 0x5f 0xe60 0x61 0xe2f 0x63 0xdc5 0x64 0xd6d>;
		r_profile_t2_num = <0x33>;
		r_profile_t2 = <0xab 0x1073 0xab 0x105e 0xac 0x1048 0xa1 0x1034 0xb2 0x1021 0xac 0x100d 0xbd 0xffc 0xae 0xfeb 0xac 0xfdd 0x9d 0xfc7 0xa4 0xfb3 0xab 0xfa1 0x9e 0xf94 0xc1 0xf8b 0xc1 0xf7e 0xbf 0xf71 0xaf 0xf63 0xcb 0xf57 0xb0 0xf4a 0xb9 0xf3a 0xb7 0xf2b 0xb5 0xf1c 0xab 0xf0f 0xb3 0xf04 0xaf 0xefb 0xb8 0xef2 0xaa 0xeeb 0x9c 0xee4 0xb8 0xedf 0xa6 0xed9 0xa9 0xed4 0xb9 0xed0 0xbb 0xecb 0xbc 0xec7 0xa8 0xec2 0xc1 0xebd 0xa7 0xeb7 0xa1 0xeb0 0xb0 0xea9 0xa2 0xea2 0xae 0xe9c 0xa4 0xe94 0xae 0xe8a 0xac 0xe7f 0xaf 0xe71 0xa7 0xe69 0xa8 0xe66 0xb2 0xe60 0xba 0xe2f 0xd0 0xdc5 0xef 0xcf2>;
	};

	bat_comm_cust_7 {
		compatible = "mediatek,battery_cust_7";
		high_battery_voltage_support = <0x0>;
		charging_full_current = <0xa0>;
	};

	bat_meter_cust_7 {
		compatible = "mediatek,bat_meter_cust_7";
		q_max_pos_50 = <0x11c6>;
		q_max_pos_25 = <0x11c6>;
		q_max_pos_0 = <0x11c6>;
		q_max_neg_10 = <0x11c6>;
		q_max_pos_50_h_current = <0x11c6>;
		q_max_pos_25_h_current = <0x11c6>;
		q_max_pos_0_h_current = <0x11c6>;
		q_max_neg_10_h_current = <0x11c6>;
		num_table = <0x1>;
		battery_profile_t2_num = <0x33>;
		battery_profile_t2 = <0x0 0x104d 0x2 0x1038 0x4 0x1024 0x6 0x1012 0x8 0x1000 0xa 0xfef 0xc 0xfe6 0xe 0xfd4 0x10 0xfb8 0x12 0xfa2 0x14 0xf95 0x16 0xf8e 0x18 0xf82 0x1a 0xf76 0x1c 0xf69 0x1e 0xf5a 0x20 0xf48 0x22 0xf36 0x24 0xf25 0x26 0xf18 0x28 0xf0c 0x2a 0xf04 0x2c 0xefb 0x2e 0xef4 0x30 0xeed 0x32 0xee5 0x34 0xedf 0x36 0xeda 0x38 0xed4 0x3a 0xece 0x3c 0xeca 0x3e 0xec4 0x40 0xebf 0x42 0xeba 0x44 0xeb5 0x46 0xeb0 0x48 0xeab 0x4b 0xea6 0x4d 0xea1 0x4f 0xe9b 0x51 0xe95 0x53 0xe8c 0x55 0xe83 0x57 0xe79 0x59 0xe6e 0x5b 0xe6a 0x5d 0xe67 0x5f 0xe63 0x61 0xe43 0x63 0xdf3 0x64 0xd6d>;
		r_profile_t2_num = <0x33>;
		r_profile_t2 = <0x8b 0x104d 0x8b 0x1038 0x89 0x1024 0x8a 0x1012 0x95 0x1000 0x8a 0xfef 0x91 0xfe6 0x9c 0xfd4 0x90 0xfb8 0x98 0xfa2 0x93 0xf95 0x94 0xf8e 0x93 0xf82 0x95 0xf76 0x94 0xf69 0xa6 0xf5a 0x98 0xf48 0x94 0xf36 0x86 0xf25 0x97 0xf18 0x88 0xf0c 0x95 0xf04 0x8e 0xefb 0x8a 0xef4 0x8a 0xeed 0x93 0xee5 0x96 0xedf 0x93 0xeda 0x96 0xed4 0x94 0xece 0x99 0xeca 0xa2 0xec4 0x96 0xebf 0x8e 0xeba 0x90 0xeb5 0x96 0xeb0 0x91 0xeab 0x97 0xea6 0x94 0xea1 0x88 0xe9b 0x96 0xe95 0x98 0xe8c 0x9e 0xe83 0xa4 0xe79 0x9e 0xe6e 0x95 0xe6a 0xa4 0xe67 0xaa 0xe63 0xa9 0xe43 0x97 0xdf3 0xa1 0xd6d>;
	};

	bat_comm_cust_8 {
		compatible = "mediatek,battery_cust_8";
		v_cc2topoff_thres = <0x1068>;
		recharging_voltage = <0x10a4>;
		high_battery_voltage_support = <0x1>;
		charging_full_current = <0x168>;
	};

	bat_meter_cust_8 {
		compatible = "mediatek,bat_meter_cust_8";
		q_max_pos_50 = <0x1a2c>;
		q_max_pos_25 = <0x1a2c>;
		q_max_pos_0 = <0x1a2c>;
		q_max_neg_10 = <0x1a2c>;
		q_max_pos_50_h_current = <0x1a2c>;
		q_max_pos_25_h_current = <0x1a2c>;
		q_max_pos_0_h_current = <0x1a2c>;
		q_max_neg_10_h_current = <0x1a2c>;
		num_table = <0x1>;
		battery_profile_t2_num = <0x3a>;
		battery_profile_t2 = <0x0 0x10fa 0x2 0x10d6 0x4 0x10bb 0x5 0x10a4 0x7 0x108e 0x9 0x107b 0xb 0x1066 0xc 0x1055 0xe 0x1042 0x10 0x102f 0x12 0x101d 0x13 0x100c 0x15 0xffa 0x17 0xfee 0x19 0xfe4 0x1b 0xfca 0x1c 0xfae 0x1e 0xf9c 0x20 0xf8e 0x22 0xf88 0x23 0xf80 0x25 0xf73 0x27 0xf65 0x29 0xf55 0x2b 0xf44 0x2c 0xf34 0x2e 0xf25 0x30 0xf19 0x32 0xf0f 0x33 0xf06 0x35 0xefd 0x37 0xef6 0x39 0xeef 0x3a 0xee8 0x3c 0xee2 0x3e 0xedd 0x40 0xed7 0x42 0xed2 0x43 0xece 0x45 0xec9 0x47 0xec4 0x49 0xebf 0x4a 0xeb9 0x4c 0xeb2 0x4e 0xeab 0x50 0xea4 0x51 0xe9f 0x53 0xe99 0x55 0xe8f 0x57 0xe87 0x59 0xe7c 0x5a 0xe6f 0x5c 0xe6d 0x5e 0xe69 0x60 0xe60 0x61 0xe2f 0x63 0xdcf 0x64 0xdb0>;
		r_profile_t2_num = <0x3a>;
		r_profile_t2 = <0x8f 0x10fa 0x8f 0x10d6 0x88 0x10bb 0x84 0x10a4 0x89 0x108e 0x88 0x107b 0x7c 0x1066 0x84 0x1055 0x8c 0x1042 0x8f 0x102f 0x91 0x101d 0x92 0x100c 0x86 0xffa 0x89 0xfee 0x9e 0xfe4 0x98 0xfca 0x87 0xfae 0x94 0xf9c 0x8b 0xf8e 0x87 0xf88 0x9b 0xf80 0x9a 0xf73 0xa0 0xf65 0x9c 0xf55 0x9c 0xf44 0x91 0xf34 0x82 0xf25 0x81 0xf19 0x86 0xf0f 0x84 0xf06 0x8b 0xefd 0x83 0xef6 0x86 0xeef 0x80 0xee8 0x85 0xee2 0x9a 0xedd 0x83 0xed7 0x89 0xed2 0x8e 0xece 0x93 0xec9 0x83 0xec4 0x8e 0xebf 0x8d 0xeb9 0x81 0xeb2 0x86 0xeab 0x84 0xea4 0x80 0xe9f 0x88 0xe99 0x8e 0xe8f 0x96 0xe87 0x83 0xe7c 0x95 0xe6f 0x97 0xe6d 0x8b 0xe69 0x8e 0xe60 0x9e 0xe2f 0x93 0xdcf 0x95 0xd24>;
	};

	bat_comm_cust_9 {
		compatible = "mediatek,battery_cust_9";
		high_battery_voltage_support = <0x0>;
		charging_full_current = <0xa0>;
	};

	bat_meter_cust_9 {
		compatible = "mediatek,bat_meter_cust_9";
		q_max_pos_50 = <0xea6>;
		q_max_pos_25 = <0xea6>;
		q_max_pos_0 = <0xea6>;
		q_max_neg_10 = <0xea6>;
		q_max_pos_50_h_current = <0xea6>;
		q_max_pos_25_h_current = <0xea6>;
		q_max_pos_0_h_current = <0xea6>;
		q_max_neg_10_h_current = <0xea6>;
		num_table = <0x1>;
		battery_profile_t2_num = <0x31>;
		battery_profile_t2 = <0x0 0x1052 0x2 0x103c 0x4 0x1028 0x6 0x1015 0x8 0x1003 0xa 0xff1 0xd 0xfe1 0xf 0xfd2 0x11 0xfbb 0x13 0xfaa 0x15 0xf9f 0x17 0xf91 0x19 0xf83 0x1b 0xf76 0x1d 0xf6a 0x1f 0xf5e 0x21 0xf51 0x23 0xf43 0x26 0xf33 0x28 0xf21 0x2a 0xf11 0x2c 0xf04 0x2e 0xefb 0x30 0xef2 0x32 0xeeb 0x34 0xee4 0x36 0xede 0x38 0xed8 0x3a 0xed3 0x3c 0xece 0x3f 0xeca 0x41 0xec5 0x43 0xec1 0x45 0xebd 0x47 0xeba 0x49 0xeb4 0x4b 0xeaf 0x4d 0xea7 0x4f 0xea0 0x51 0xe99 0x53 0xe8f 0x55 0xe83 0x57 0xe74 0x5a 0xe6a 0x5c 0xe67 0x5e 0xe66 0x60 0xe5e 0x62 0xe1c 0x64 0xda2>;
		r_profile_t2_num = <0x31>;
		r_profile_t2 = <0x84 0x1052 0x84 0x103c 0x6b 0x1028 0x78 0x1015 0x83 0x1003 0x7c 0xff1 0x7a 0xfe1 0x85 0xfd2 0x85 0xfbb 0x85 0xfaa 0x84 0xf9f 0x88 0xf91 0x9b 0xf83 0x93 0xf76 0x8c 0xf6a 0x9c 0xf5e 0x9c 0xf51 0x91 0xf43 0x90 0xf33 0x89 0xf21 0x95 0xf11 0x8b 0xf04 0x7e 0xefb 0x7a 0xef2 0x85 0xeeb 0x7a 0xee4 0x80 0xede 0x7b 0xed8 0x7f 0xed3 0x8d 0xece 0x7f 0xeca 0x80 0xec5 0x89 0xec1 0x89 0xebd 0x8a 0xeba 0x8b 0xeb4 0x91 0xeaf 0x84 0xea7 0x81 0xea0 0x85 0xe99 0x7c 0xe8f 0x72 0xe83 0x85 0xe74 0x7f 0xe6a 0x84 0xe67 0x81 0xe66 0x82 0xe5e 0x85 0xe1c 0x98 0xda2>;
	};

	bat_comm_cust_a {
		compatible = "mediatek,battery_cust_a";
		high_battery_voltage_support = <0x0>;
		charging_full_current = <0x104>;
		jlink_cust_system_off = <0xdb6>;
		v_0percent_tracking = <0xde8>;
	};

	bat_meter_cust_a {
		compatible = "mediatek,bat_meter_cust_a";
		jlink_norminal_capacity = <0xfa0>;
		q_max_pos_50 = <0x1053>;
		q_max_pos_25 = <0x1053>;
		q_max_pos_0 = <0x1053>;
		q_max_neg_10 = <0x1053>;
		q_max_pos_50_h_current = <0x1053>;
		q_max_pos_25_h_current = <0x1053>;
		q_max_pos_0_h_current = <0x1053>;
		q_max_neg_10_h_current = <0x1053>;
		num_table = <0x1>;
		battery_profile_t2_num = <0x39>;
		battery_profile_t2 = <0x0 0x104a 0x2 0x101b 0x4 0x1004 0x5 0xff6 0x7 0xfec 0x9 0xfe4 0xb 0xfdf 0xd 0xfda 0xf 0xfd6 0x10 0xfd3 0x12 0xfd0 0x14 0xfce 0x16 0xfcc 0x18 0xfcb 0x19 0xfc9 0x1b 0xfc7 0x1d 0xfc5 0x1f 0xfc3 0x21 0xfc1 0x22 0xfbd 0x24 0xfb6 0x26 0xfac 0x28 0xfa0 0x2a 0xf97 0x2c 0xf8c 0x2d 0xf81 0x2f 0xf76 0x31 0xf6b 0x33 0xf5e 0x35 0xf53 0x36 0xf48 0x38 0xf3f 0x3a 0xf38 0x3c 0xf32 0x3e 0xf2d 0x3f 0xf29 0x41 0xf26 0x43 0xf22 0x45 0xf1d 0x47 0xf17 0x49 0xf10 0x4a 0xf08 0x4c 0xeff 0x4e 0xef6 0x50 0xeed 0x52 0xee4 0x53 0xed8 0x55 0xecb 0x57 0xebe 0x59 0xeaf 0x5b 0xe9f 0x5d 0xe96 0x5e 0xe8c 0x60 0xe7f 0x62 0xe5e 0x64 0xe01 0x64 0xd8a>;
		r_profile_t2_num = <0x39>;
		r_profile_t2 = <0x71 0x104a 0x71 0x101b 0x63 0x1004 0x64 0xff6 0x75 0xfec 0x5e 0xfe4 0x75 0xfdf 0x6c 0xfda 0x60 0xfd6 0x65 0xfd3 0x5a 0xfd0 0x67 0xfce 0x6a 0xfcc 0x70 0xfcb 0x6b 0xfc9 0x63 0xfc7 0x65 0xfc5 0x6c 0xfc3 0x74 0xfc1 0x72 0xfbd 0x70 0xfb6 0x6f 0xfac 0x6a 0xfa0 0x68 0xf97 0x66 0xf8c 0x5f 0xf81 0x69 0xf76 0x66 0xf6b 0x67 0xf5e 0x6b 0xf53 0x5f 0xf48 0x6d 0xf3f 0x66 0xf38 0x59 0xf32 0x6a 0xf2d 0x59 0xf29 0x66 0xf26 0x6d 0xf22 0x68 0xf1d 0x61 0xf17 0x61 0xf10 0x66 0xf08 0x66 0xeff 0x5c 0xef6 0x66 0xeed 0x68 0xee4 0x5f 0xed8 0x5f 0xecb 0x6b 0xebe 0x6e 0xeaf 0x64 0xe9f 0x5c 0xe96 0x6f 0xe8c 0x69 0xe7f 0x6b 0xe5e 0x73 0xe0b 0x8b 0xd8a>;
	};

	bat_comm_cust_b {
		compatible = "mediatek,battery_cust_b";
		high_battery_voltage_support = <0x0>;
		charging_full_current = <0x104>;
		jlink_cust_system_off = <0xd48>;
	};

	bat_meter_cust_b {
		compatible = "mediatek,bat_meter_cust_b";
		jlink_norminal_capacity = <0x1770>;
		q_max_pos_50 = <0x16a8>;
		q_max_pos_25 = <0x16a8>;
		q_max_pos_0 = <0x16a8>;
		q_max_neg_10 = <0x16a8>;
		q_max_pos_50_h_current = <0x16a8>;
		q_max_pos_25_h_current = <0x16a8>;
		q_max_pos_0_h_current = <0x16a8>;
		q_max_neg_10_h_current = <0x16a8>;
		num_table = <0x1>;
		battery_profile_t2_num = <0x3b>;
		battery_profile_t2 = <0x0 0x105e 0x2 0x103d 0x4 0x1021 0x6 0x1008 0x8 0xff0 0xb 0xfd8 0xd 0xfc1 0xf 0xfab 0x11 0xf96 0x13 0xf81 0x15 0xf6c 0x17 0xf57 0x19 0xf43 0x1b 0xf2f 0x1d 0xf1c 0x20 0xf08 0x22 0xef4 0x24 0xee0 0x26 0xecc 0x28 0xeba 0x2a 0xea7 0x2c 0xe96 0x2e 0xe87 0x30 0xe78 0x32 0xe6b 0x35 0xe5f 0x37 0xe55 0x39 0xe4c 0x3b 0xe44 0x3d 0xe3d 0x3f 0xe37 0x41 0xe32 0x43 0xe2c 0x45 0xe28 0x47 0xe23 0x4a 0xe1d 0x4c 0xe17 0x4e 0xe11 0x50 0xe09 0x52 0xe01 0x54 0xdf7 0x56 0xdec 0x58 0xde0 0x5a 0xdd5 0x5c 0xdcb 0x5f 0xdbf 0x61 0xdb2 0x63 0xda4 0x64 0xd95 0x64 0xd85 0x64 0xd78 0x64 0xd6a 0x64 0xd54 0x64 0xd1b 0x64 0xcee 0x64 0xcdd 0x64 0xcd6 0x64 0xcd6 0x64 0xcd0>;
		r_profile_t2_num = <0x3b>;
		r_profile_t2 = <0x54 0x105e 0x54 0x103d 0x4d 0x1021 0x50 0x1008 0x56 0xff0 0x52 0xfd8 0x50 0xfc1 0x50 0xfab 0x4f 0xf96 0x51 0xf81 0x50 0xf6c 0x51 0xf57 0x56 0xf43 0x50 0xf2f 0x4d 0xf1c 0x57 0xf08 0x50 0xef4 0x5b 0xee0 0x5f 0xecc 0x61 0xeba 0x54 0xea7 0x59 0xe96 0x58 0xe87 0x4d 0xe78 0x4d 0xe6b 0x4d 0xe5f 0x4e 0xe55 0x4d 0xe4c 0x50 0xe44 0x47 0xe3d 0x54 0xe37 0x44 0xe32 0x55 0xe2c 0x4a 0xe28 0x4b 0xe23 0x53 0xe1d 0x44 0xe17 0x52 0xe11 0x58 0xe09 0x4f 0xe01 0x4f 0xdf7 0x47 0xdec 0x45 0xde0 0x4e 0xdd5 0x4e 0xdcb 0x4f 0xdbf 0x58 0xdb2 0x52 0xda4 0x5b 0xd95 0x5f 0xd85 0x65 0xd78 0x73 0xd6a 0x89 0xd54 0xd2 0xd1b 0xe3 0xcee 0xc9 0xcdd 0xa6 0xcd6 0x93 0xcd6 0x95 0xcd0>;
	};

	bat_comm_cust_c {
		compatible = "mediatek,battery_cust_c";
		high_battery_voltage_support = <0x0>;
		charging_full_current = <0x104>;
		jlink_cust_system_off = <0xd48>;
	};

	bat_meter_cust_c {
		compatible = "mediatek,bat_meter_cust_c";
		jlink_norminal_capacity = <0xe10>;
		q_max_pos_50 = <0xd49>;
		q_max_pos_25 = <0xd49>;
		q_max_pos_0 = <0xd49>;
		q_max_neg_10 = <0xd49>;
		q_max_pos_50_h_current = <0xd49>;
		q_max_pos_25_h_current = <0xd49>;
		q_max_pos_0_h_current = <0xd49>;
		q_max_neg_10_h_current = <0xd49>;
		num_table = <0x1>;
		battery_profile_t2_num = <0x31>;
		battery_profile_t2 = <0x0 0x103a 0x2 0x1011 0x4 0xff6 0x6 0xfe4 0x8 0xfd4 0xb 0xfc9 0xd 0xfc5 0xf 0xfbf 0x11 0xfb5 0x13 0xfaa 0x15 0xf9b 0x17 0xf8a 0x19 0xf7b 0x1b 0xf6c 0x1e 0xf5e 0x20 0xf55 0x22 0xf4c 0x24 0xf43 0x26 0xf38 0x28 0xf2e 0x2a 0xf21 0x2c 0xf13 0x2e 0xf03 0x31 0xef1 0x33 0xee1 0x35 0xed4 0x37 0xeca 0x39 0xec5 0x3b 0xec3 0x3d 0xec1 0x3f 0xeb9 0x41 0xeac 0x44 0xe9b 0x46 0xe86 0x48 0xe72 0x4a 0xe60 0x4c 0xe51 0x4e 0xe42 0x50 0xe35 0x52 0xe27 0x54 0xe19 0x57 0xe0b 0x59 0xdfd 0x5b 0xdee 0x5d 0xddb 0x5f 0xdc7 0x61 0xdb2 0x63 0xd9f 0x64 0xd91>;
		r_profile_t2_num = <0x31>;
		r_profile_t2 = <0x73 0x103a 0x73 0x1011 0x80 0xff6 0x7a 0xfe4 0x77 0xfd4 0x69 0xfc9 0x63 0xfc5 0x86 0xfbf 0x7a 0xfb5 0x87 0xfaa 0x7b 0xf9b 0x69 0xf8a 0x77 0xf7b 0x85 0xf6c 0x80 0xf5e 0x88 0xf55 0x92 0xf4c 0x80 0xf43 0x86 0xf38 0x91 0xf2e 0x89 0xf21 0x87 0xf13 0x88 0xf03 0x76 0xef1 0x72 0xee1 0x81 0xed4 0x7a 0xeca 0x7a 0xec5 0x7a 0xec3 0x86 0xec1 0x76 0xeb9 0x85 0xeac 0x85 0xe9b 0x77 0xe86 0x6b 0xe72 0x80 0xe60 0x83 0xe51 0x80 0xe42 0x7b 0xe35 0x7d 0xe27 0x84 0xe19 0x7a 0xe0b 0x74 0xdfd 0x81 0xdee 0x84 0xddb 0x85 0xdc7 0x83 0xdb2 0x89 0xd9f 0x8e 0xd91>;
	};
};
